# NANO103AE_v1 register map
File version: 1.0
Registers are 32-bit, read-write, reset 0x0 unless marked. A register's access mark holds for its fields unless they carry their own. Offsets are from the block's base; [hi:lo] are bit positions; {n}, {i} and the like mark numbered series.

## PDMA_CH1 — PDMA Register Map
Base 0x50008100
Same registers: PDMA_CH2 0x50008200, PDMA_CH3 0x50008300, PDMA_CH4 0x50008400
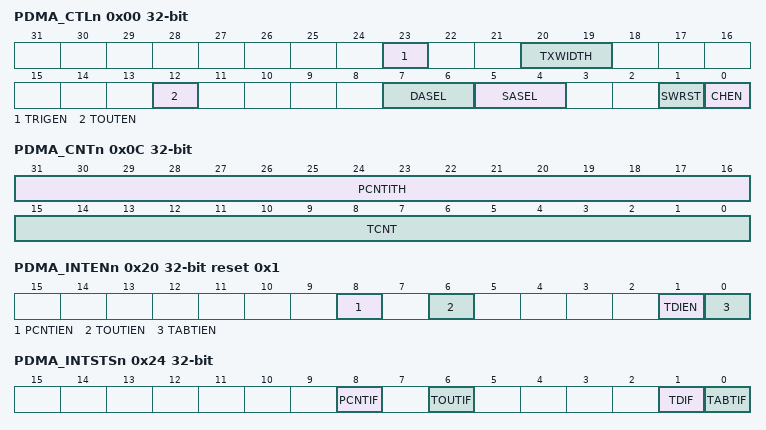
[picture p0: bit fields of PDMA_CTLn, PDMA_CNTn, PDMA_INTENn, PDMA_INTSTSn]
0x00 PDMA_CTLn — PDMA Channel n Control Register
  [23] TRIGEN — Trigger Enable Bit. Note1: When PDMA transfer completed, this bit will be cleared automatically. Note2: If the bus error occurs, all PDMA transfer will be stopped. User must reset all PDMA channels, and then trigger again.
    0=No effect; 1=PDMA data transfer Enabled
  [20:19] TXWIDTH — Transfer Width Selection. This field is used for transfer width.
    0=One word (32-bit) is transferred for every PDMA operation; 1=One byte (8-bit) is transferred for every PDMA operation; 2=One half-word (16-bit) is transferred for every PDMA operation
  [12] TOUTEN — Time-out Enable Bit
    0=PDMA internal counter Disabled; 1=PDMA internal counter Enabled
  [7:6] DASEL — Transfer Destination Address Direction Selection
    0=Transfer Destination address is incremented successively; 2=Transfer Destination address is fixed. (This feature can be used when data transferred from multiple sources to a single destination); 3=Transfer Destination address is wrapped around (When the PDMA_CCNT is equal to 0, the PDMA_CDA and PDMA_CCNT registers will be updated by PDMA_DA and PDMA_CNT automatically. PDMA will start another transfer without user trigger until CHEN disabled. When the CHEN is disabled, the PDMA will complete the active transfer but the remained data which in the PDMA buffer will not transfer to destination address)
  [5:4] SASEL — Transfer Source Address Direction Selection
    0=Transfer Source address is incremented successively; 2=Transfer Source address is fixed (This feature can be used when data where transferred from a single source to multiple destinations); 3=Transfer Source address is wrap around (When the PDMA_CCNT is equal to 0, the PDMA_CSA and PDMA_CCNT registers will be updated by PDMA_SA and PDMA_CNT automatically. PDMA will start another transfer without user trigger until CHEN disabled. When the CHEN is disabled, the PDMA will complete the active transfer but the remained data which in the PDMA buffer will not transfer to destination address)
  [1] SWRST — Software Engine Reset
    0=No effect; 1=Reset the internal state machine, pointers and internal buffer. The contents of all control registers will not be cleared. This bit will be automatically cleared after few clock cycles
  [0] CHEN — PDMA Channel Enable Bit. Setting this bit to 1 enables PDMA operation. If this bit is cleared, PDMA will ignore all PDMA request and force Bus Master into IDLE state.
0x04 PDMA_SAn — PDMA Channel n Source Address Register
  [31:0] SA — PDMA Transfer Source Address Bits. This field indicates a 32-bit source address of PDMA. Note: The source address must be word alignment.
0x08 PDMA_DAn — PDMA Channel n Destination Address Register
  [31:0] DA — PDMA Transfer Destination Address Bits. This field indicates a 32-bit destination address of PDMA. Note: The Destination address must be word alignment.
0x0C PDMA_CNTn — PDMA Channel n Transfer Count Register
  [31:16] PCNTITH — PDMA Periodic Count Interrupt Threshold. This field indicates how many data transferred to generate periodic interrupt. Note: write 0 to this field to disable this function.
  [15:0] TCNT — PDMA Transfer Count Bits. This field indicates a 16-bit transfer count number of PDMA.
0x14 PDMA_CSAn ro — PDMA Channel n Current Source Address Register
  [31:0] CSA — PDMA Current Source Address Bits (Read Only). This field indicates the source address where the PDMA transfer just occurred.
0x18 PDMA_CDAn ro — PDMA Channel n Current Destination Address Register
  [31:0] CDA — PDMA Current Destination Address Bits (Read Only). This field indicates the destination address where the PDMA transfer just occurred.
0x1C PDMA_CCNTn ro — PDMA Channel n Current Transfer Count Register
  [15:0] CCNT — PDMA Current Count Bits (Read Only). This field indicates the current remained transfer count of PDMA.
0x20 PDMA_INTENn reset 0x1 — PDMA Channel n Interrupt Enable Register
  [8] PCNTIEN — Periodic Count Interrupt Enable Bit. This field indicates how many data transferred to generate interrupt periodically.
    0=Periodic transfer count interrupt Disabled; 1=Periodic transfer count interrupt Enabled
  [6] TOUTIEN — Time-out Interrupt Enable Bit
    0=Time-out interrupt Disabled; 1=Time-out interrupt Enabled
  [1] TDIEN — PDMA Transfer Done Interrupt Enable Bit
    0=Interrupt Disabled when PDMA transfer is done; 1=Interrupt Enabled when PDMA transfer is done
  [0] TABTIEN — PDMA Read/Write Target Abort Interrupt Enable Bit
    0=Target abort interrupt Disabled during PDMA transfer; 1=Target abort interrupt Enabled during PDMA transfer
0x24 PDMA_INTSTSn — PDMA Channel n Interrupt Status Register
  [8] PCNTIF — Periodic Count Interrupt Status Flag. Note: This bit is cleared by writing "1" to it.
  [6] TOUTIF — Time-out Interrupt Status Flag. This flag indicated that PDMA has waited peripheral request for a period defined by PDMA_TOC. Note: This bit is cleared by writing "1" to it.
    0=No time-out flag; 1=Time-out flag
  [1] TDIF — Transfer Done Interrupt Status Flag. This bit indicates that PDMA has finished all transfer. Note: This bit is cleared by writing "1" to it.
    0=Not finished yet; 1=Done
  [0] TABTIF — PDMA Read/Write Target Abort Interrupt Status Flag. Note1: This bit is cleared by writing "1" to it. Note2: This bit indicates bus master received error response or not, if bus master received error response, it means that PDMA transfer data from an invalid address or to an invalid adress .At this time target abort is happened..PDMA controller will stop transfer and respond this event to user then go to IDLE state. When target abort occurred, user must reset PDMA controller, and then transfer those data again.
    0=No bus ERROR response received; 1=Bus ERROR response received
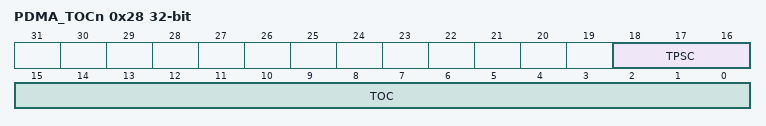
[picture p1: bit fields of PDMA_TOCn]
0x28 PDMA_TOCn — PDMA Channel n Time-out Counter Register
  [18:16] TPSC — PDMA Time-out Counter Clock Source Prescaler
    0=PDMA time-out clock source is HCLK/28; 1=PDMA time-out clock source is HCLK/29; {v}=PDMA time-out clock source is HCLK/{v+208} (v=2..7)
  [15:0] TOC — PDMA Time-out Period Counter
